# MCXN947_cm33_core0 register map
Vendor: nxp.com; File version: 1.0
CPU: CM33 r2p0, little endian, MPU, FPU, VTOR, 3 interrupt priority bits
Registers are 32-bit, read-write, reset 0x0 unless marked. A register's access mark holds for its fields unless they carry their own. Offsets are from the block's base; [hi:lo] are bit positions; 'fields as' and 'values as' point back to an identical list.

## DAC0 — 12-bit DAC
Base 0x4010F000
Same registers: DAC1 0x40112000
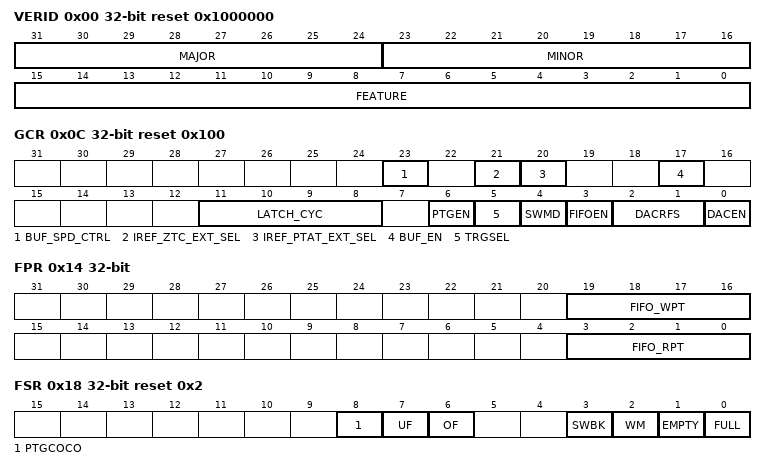
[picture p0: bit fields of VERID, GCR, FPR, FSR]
0x00 VERID ro reset 0x1000000 — Version Identifier
  [31:24] MAJOR — Major Version Number
  [23:16] MINOR — Minor Version Number
  [15:0] FEATURE — Feature Identification Number
0x04 PARAM ro reset 0x3 — Parameter
  [2:0] FIFOSZ — FIFO Size
    1=FIFO depth is 4; 2=FIFO depth is 8; 3=FIFO depth is 16; 4=FIFO depth is 32; 5=FIFO depth is 64; 6=FIFO depth is 128; 7=FIFO depth is 256
0x08 DATA
  [11:0] DATA — FIFO Entry or Buffer Entry
0x0C GCR reset 0x100 — Global Control
  [23] BUF_SPD_CTRL — OPAMP as Buffer, Speed Control Signal
    0=LLP_MODE (Lower Low-Power mode); 1=LP_MODE (Low-Power mode)
  [21] IREF_ZTC_EXT_SEL — External On-Chip ZTC Current Reference Select
    0=NOT_SELECTED; 1=SELECTED
  [20] IREF_PTAT_EXT_SEL — External On-Chip PTAT Current Reference Select
    0=NOT_SELECTED; 1=SELECTED
  [17] BUF_EN — Buffer Enable
    0=USE_BUF (Not used); 1=NO_USE_BUF (Used)
  [11:8] LATCH_CYC — RCLK Cycles Before Data Latch
  [6] PTGEN — DAC Periodic Trigger Mode Enable
    0=DISABLED (Disables); 1=ENABLED (Enables)
  [5] TRGSEL — DAC Trigger Select
    0=HARDWARE (Hardware trigger); 1=SOFTWARE (Software trigger)
  [4] SWMD — Swing Back Mode
    0=DISABLE (Disables); 1=ENABLE (Enables)
  [3] FIFOEN — FIFO Enable
    0=BUFFER_MODE (Enables FIFO mode and disables Buffer mode. Any data written to goes to buffer then goes to conversion.); 1=FIFO_MODE (Enables FIFO mode. Data will be first read from FIFO to buffer and then goes to conversion.)
  [2:1] DACRFS — DAC Reference Select
    0=VREFH0 (Selects VREFH0 as the reference voltage); 1=VREFH1 (Selects VREFH1 as the reference voltage); 2=VREFH2 (Selects VREFH2 as the reference voltage)
  [0] DACEN — DAC Enable
    0=DISABLED (Disables); 1=ENABLED (Enables)
0x10 FCR — DAC FIFO Control
  [3:0] WML — Watermark Level
0x14 FPR ro — DAC FIFO Pointer
  [19:16] FIFO_WPT — FIFO Write Pointer
  [3:0] FIFO_RPT — FIFO Read Pointer
0x18 FSR reset 0x2 — FIFO Status
  [8] PTGCOCO write-1-clears — Period Trigger Mode Conversion Complete Flag
    0=NOT_START (Not completed or not started); 1=COMPLETED
  [7] UF write-1-clears — FIFO Underflow Flag
    0=NO_UNDERFLOW (No underflow has occurred since the last time the flag was cleared); 1=UNDERFLOW (At least one trigger underflow has occurred since the last time the flag was cleared)
  [6] OF write-1-clears — FIFO Overflow Flag
    0=NO_OVERFLOW (No overflow has occurred since the last time the flag was cleared); 1=OVERFLOW (At least one FIFO overflow has occurred since the last time the flag was cleared)
  [3] SWBK write-1-clears — Swing Back One Cycle Complete Flag
    0=NO_SWING (No swing back cycle has completed since the last time the flag was cleared); 1=SWING_BACK (At least one swing back cycle has occurred since the last time the flag was cleared)
  [2] WM ro — FIFO Watermark Status Flag
    0=MORE_THAN_WLEVEL (Data in FIFO is more than watermark level); 1=LESS_THAN_WLEVEL (Data in FIFO is less than or equal to watermark level)
  [1] EMPTY ro — FIFO Empty Flag
    0=NOT_EMPTY; 1=EMPTY
  [0] FULL ro — FIFO Full Flag
    0=NOT_FULL; 1=FULL
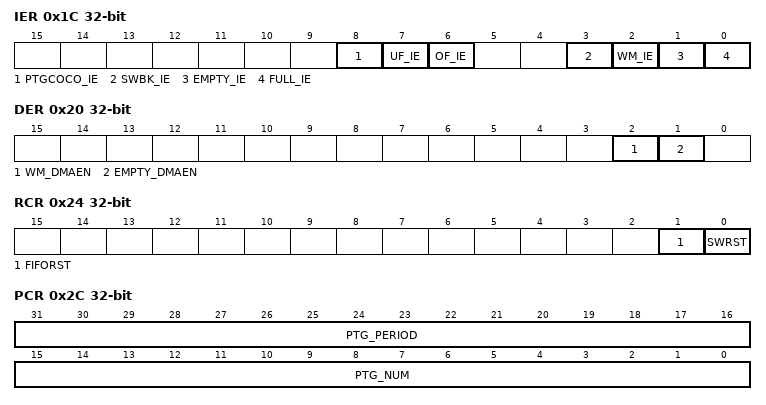
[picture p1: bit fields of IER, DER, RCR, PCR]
0x1C IER — Interrupt Enable
  [all] fields
    0=DISABLED (Disables); 1=ENABLED (Enables)
  [8] PTGCOCO_IE — PTG Mode Conversion Complete Interrupt Enable
  [7] UF_IE — FIFO Underflow Interrupt Enable
  [6] OF_IE — FIFO Overflow Interrupt Enable
  [3] SWBK_IE — Swing Back One Cycle Complete Interrupt Enable
  [2] WM_IE — FIFO Watermark Interrupt Enable
  [1] EMPTY_IE — FIFO Empty Interrupt Enable
  [0] FULL_IE — FIFO Full Interrupt Enable
0x20 DER — DMA Enable
  [2] WM_DMAEN — FIFO Watermark DMA Enable
    0=DISABLED (Disables); 1=ENABLED (Enables)
  [1] EMPTY_DMAEN — FIFO Empty DMA Enable
    0=DISABLED (Disables); 1=ENABLED (Enables)
0x24 RCR — Reset Control
  [1] FIFORST — FIFO Reset
    0=NO_EFFECT; 1=FIFO_RESET
  [0] SWRST — Software Reset
    0=NO_EFFECT; 1=SOFTWARE_RESET
0x28 TCR — Trigger Control
  [0] SWTRG — Software Trigger
    0=NOT_VALID; 1=VALID
0x2C PCR — Periodic Trigger Control
  [31:16] PTG_PERIOD — Periodic Trigger Period Width
  [15:0] PTG_NUM — Periodic Trigger Number

## DAC2 — 14-bit DAC
Base 0x40114000
Registers as DAC0; these are added or differ:
0x04 PARAM ro reset 0x4 — Parameter
  [2:0] FIFOSZ — FIFO Size
    1=FIFO depth is 4; 2=FIFO depth is 8; 3=FIFO depth is 16; 4=FIFO depth is 32; 5=FIFO depth is 64; 6=FIFO depth is 128; 7=FIFO depth is 256
0x08 DATA
  [13:0] DATA — FIFO Entry or Buffer Entry
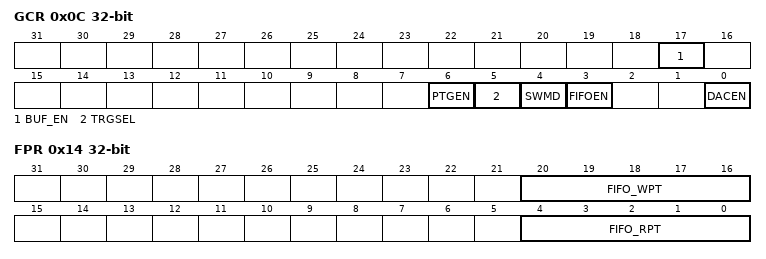
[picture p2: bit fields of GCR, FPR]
0x0C GCR — Global Control
  [17] BUF_EN — Buffer Enable
    0=USE_BUF (Not used); 1=NO_USE_BUF (Used)
  [6] PTGEN — DAC Periodic Trigger Mode Enable
    0=DISABLED (Disables); 1=ENABLED (Enables)
  [5] TRGSEL — DAC Trigger Select
    0=HARDWARE (Hardware trigger); 1=SOFTWARE (Software trigger)
  [4] SWMD — Swing Back Mode
    0=DISABLE (Disables); 1=ENABLE (Enables)
  [3] FIFOEN — FIFO Enable
    values as DAC0.GCR.FIFOEN
  [0] DACEN — DAC Enable
    0=DISABLED (Disables); 1=ENABLED (Enables)
0x10 FCR — DAC FIFO Control
  [4:0] WML — Watermark Level
0x14 FPR ro — DAC FIFO Pointer
  [20:16] FIFO_WPT — FIFO Write Pointer
  [4:0] FIFO_RPT — FIFO Read Pointer
